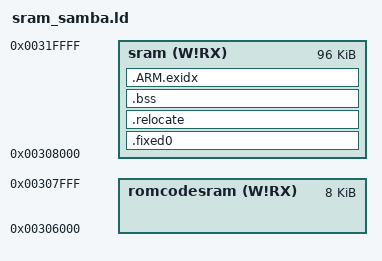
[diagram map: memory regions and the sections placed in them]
/* ----------------------------------------------------------------------------
 *         ATMEL Microcontroller Software Support
 * ----------------------------------------------------------------------------
 * Copyright (c) 2012, Atmel Corporation
 *
 * All rights reserved.
 *
 * Redistribution and use in source and binary forms, with or without
 * modification, are permitted provided that the following conditions are met:
 *
 * - Redistributions of source code must retain the above copyright notice,
 * this list of conditions and the disclaimer below.
 *
 * Atmel's name may not be used to endorse or promote products derived from
 * this software without specific prior written permission.
 *
 * DISCLAIMER: THIS SOFTWARE IS PROVIDED BY ATMEL "AS IS" AND ANY EXPRESS OR
 * IMPLIED WARRANTIES, INCLUDING, BUT NOT LIMITED TO, THE IMPLIED WARRANTIES OF
 * MERCHANTABILITY, FITNESS FOR A PARTICULAR PURPOSE AND NON-INFRINGEMENT ARE
 * DISCLAIMED. IN NO EVENT SHALL ATMEL BE LIABLE FOR ANY DIRECT, INDIRECT,
 * INCIDENTAL, SPECIAL, EXEMPLARY, OR CONSEQUENTIAL DAMAGES (INCLUDING, BUT NOT
 * LIMITED TO, PROCUREMENT OF SUBSTITUTE GOODS OR SERVICES; LOSS OF USE, DATA,
 * OR PROFITS; OR BUSINESS INTERRUPTION) HOWEVER CAUSED AND ON ANY THEORY OF
 * LIABILITY, WHETHER IN CONTRACT, STRICT LIABILITY, OR TORT (INCLUDING
 * NEGLIGENCE OR OTHERWISE) ARISING IN ANY WAY OUT OF THE USE OF THIS SOFTWARE,
 * EVEN IF ADVISED OF THE POSSIBILITY OF SUCH DAMAGE.
 * ----------------------------------------------------------------------------
 */

/*------------------------------------------------------------------------------
 *      Linker script for running in internal SRAM on the AT91SAMA5MIURA
 *----------------------------------------------------------------------------*/

OUTPUT_FORMAT("elf32-littlearm", "elf32-littlearm", "elf32-littlearm")
OUTPUT_ARCH(arm)
ENTRY(entry)
SEARCH_DIR(.)

/* Memory Spaces Definitions */
MEMORY
{
    romcodesram (W!RX) : ORIGIN = 0x306000, LENGTH = 0x2000
    sram (W!RX) : ORIGIN = 0x308000, LENGTH = 0x18000 /* sram, 96K */
}


/* Section Definitions */ 
SECTIONS 
{ 
    .fixed0 : 
    { 
        . = ALIGN(4);
        _sfixed = .;
        KEEP(*(.textisp .textisp.*))
        *(.text .text.* .gnu.linkonce.t.*) 
        *(.glue_7t) *(.glue_7)
        *(.CP15_*)
        *(.rodata .rodata* .gnu.linkonce.r.*)
        *(.ARM.extab* .gnu.linkonce.armextab.*)

        /* Support C constructors, and C destructors in both user code
           and the C library. This also provides support for C++ code. */
        . = ALIGN(4);
        KEEP(*(.init))
        . = ALIGN(4);
        __preinit_array_start = .;
        KEEP (*(.preinit_array))
        __preinit_array_end = .;

        . = ALIGN(4);
        __init_array_start = .;
        KEEP (*(SORT(.init_array.*)))
        KEEP (*(.init_array))
        __init_array_end = .;

        . = ALIGN(0x4);
        KEEP (*crtbegin.o(.ctors))
        KEEP (*(EXCLUDE_FILE (*crtend.o) .ctors))
        KEEP (*(SORT(.ctors.*)))
        KEEP (*crtend.o(.ctors))

        . = ALIGN(4);
        KEEP(*(.fini))

        . = ALIGN(4);
        __fini_array_start = .;
        KEEP (*(.fini_array))
        KEEP (*(SORT(.fini_array.*)))
        __fini_array_end = .;

        KEEP (*crtbegin.o(.dtors))
        KEEP (*(EXCLUDE_FILE (*crtend.o) .dtors))
        KEEP (*(SORT(.dtors.*)))
        KEEP (*crtend.o(.dtors))
        *(.data .data.*);
        . = ALIGN(4);
        _efixed = .;  /* End of text section */
    } > sram

    . = ALIGN(4); 
    _etext = .;

    .relocate : AT (_etext)
    {
        . = ALIGN(4);
        _srelocate = .;
        . = ALIGN(4);
        _erelocate = .;
    } > sram

    /* .bss section which is used for uninitialized data */ 
    .bss (NOLOAD) :
    { 
       . = ALIGN(4);
        _sbss = . ;
        _szero = .;
        *(.bss .bss.*)
        *(COMMON)
        . = ALIGN(4);
        _ebss = . ;
        _ezero = .;
    } > sram

    /* .ARM.exidx is sorted, so has to go in its own output section.  */
    PROVIDE_HIDDEN (__exidx_start = .);
    .ARM.exidx :
    {
      *(.ARM.exidx* .gnu.linkonce.armexidx.*)
    } > sram
    PROVIDE_HIDDEN (__exidx_end = .);
    PROVIDE(_heap =  0x31E000);
    _sstack = 0x320000;
    . = ALIGN(4); 
    _end = . ; 
}
end = .;

